AUTOSAR XML (schema 4-0-3)
package /CFLR_Code_pkg/CFLR_Code_swc
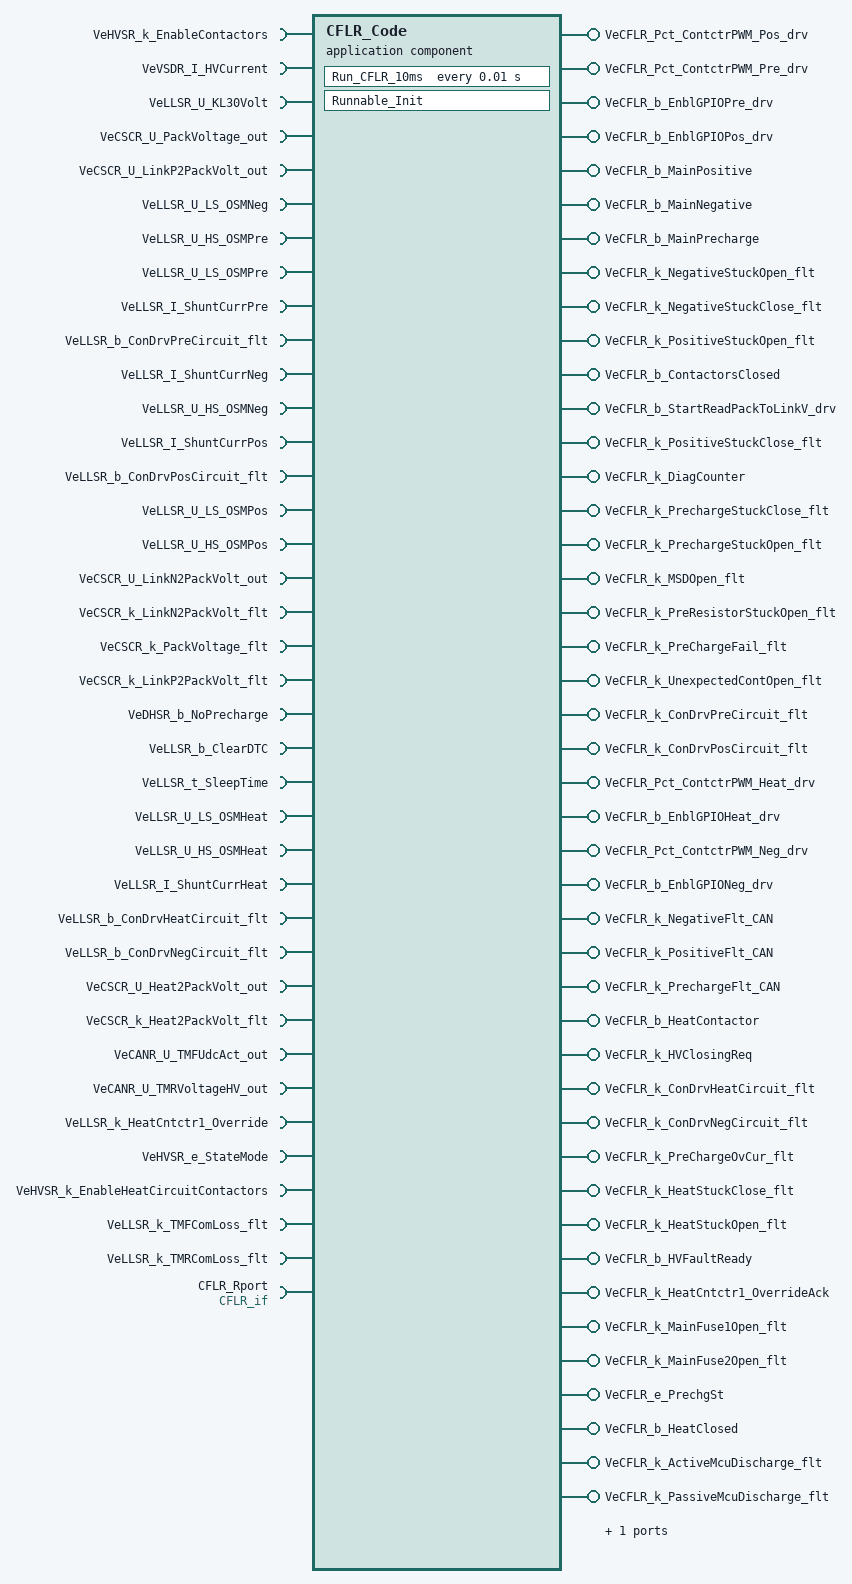
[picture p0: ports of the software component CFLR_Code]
  application sw component type CFLR_Code
    37 x require port:
      VeHVSR_k_EnableContactors: nonqueued-receiver-com-spec{data-element=VeHVSR_k_EnableContactors, init-value=0}, required-interface=VeHVSR_k_EnableContactors
      VeVSDR_I_HVCurrent: nonqueued-receiver-com-spec{data-element=VeVSDR_I_HVCurrent, init-value=0}, required-interface=VeVSDR_I_HVCurrent
      VeLLSR_U_KL30Volt: nonqueued-receiver-com-spec{data-element=VeLLSR_U_KL30Volt, init-value=0}, required-interface=VeLLSR_U_KL30Volt
      VeCSCR_U_PackVoltage_out: nonqueued-receiver-com-spec{data-element=VeCSCR_U_PackVoltage_out, init-value=0}, required-interface=VeCSCR_U_PackVoltage_out
      VeCSCR_U_LinkP2PackVolt_out: nonqueued-receiver-com-spec{data-element=VeCSCR_U_LinkP2PackVolt_out, init-value=0}, required-interface=VeCSCR_U_LinkP2PackVolt_out
      VeLLSR_U_LS_OSMNeg: nonqueued-receiver-com-spec{data-element=VeLLSR_U_LS_OSMNeg, init-value=0}, required-interface=VeLLSR_U_LS_OSMNeg
      VeLLSR_U_HS_OSMPre: nonqueued-receiver-com-spec{data-element=VeLLSR_U_HS_OSMPre, init-value=0}, required-interface=VeLLSR_U_HS_OSMPre
      VeLLSR_U_LS_OSMPre: nonqueued-receiver-com-spec{data-element=VeLLSR_U_LS_OSMPre, init-value=0}, required-interface=VeLLSR_U_LS_OSMPre
      VeLLSR_I_ShuntCurrPre: nonqueued-receiver-com-spec{data-element=VeLLSR_I_ShuntCurrPre, init-value=0}, required-interface=VeLLSR_I_ShuntCurrPre
      VeLLSR_b_ConDrvPreCircuit_flt: nonqueued-receiver-com-spec{data-element=VeLLSR_b_ConDrvPreCircuit_flt, init-value=0}, required-interface=VeLLSR_b_ConDrvPreCircuit_flt
      VeLLSR_I_ShuntCurrNeg: nonqueued-receiver-com-spec{data-element=VeLLSR_I_ShuntCurrNeg, init-value=0}, required-interface=VeLLSR_I_ShuntCurrNeg
      VeLLSR_U_HS_OSMNeg: nonqueued-receiver-com-spec{data-element=VeLLSR_U_HS_OSMNeg, init-value=0}, required-interface=VeLLSR_U_HS_OSMNeg
      VeLLSR_I_ShuntCurrPos: nonqueued-receiver-com-spec{data-element=VeLLSR_I_ShuntCurrPos, init-value=0}, required-interface=VeLLSR_I_ShuntCurrPos
      VeLLSR_b_ConDrvPosCircuit_flt: nonqueued-receiver-com-spec{data-element=VeLLSR_b_ConDrvPosCircuit_flt, init-value=0}, required-interface=VeLLSR_b_ConDrvPosCircuit_flt
      VeLLSR_U_LS_OSMPos: nonqueued-receiver-com-spec{data-element=VeLLSR_U_LS_OSMPos, init-value=0}, required-interface=VeLLSR_U_LS_OSMPos
      VeLLSR_U_HS_OSMPos: nonqueued-receiver-com-spec{data-element=VeLLSR_U_HS_OSMPos, init-value=0}, required-interface=VeLLSR_U_HS_OSMPos
      VeCSCR_U_LinkN2PackVolt_out: nonqueued-receiver-com-spec{data-element=VeCSCR_U_LinkN2PackVolt_out, init-value=0}, required-interface=VeCSCR_U_LinkN2PackVolt_out
      VeCSCR_k_LinkN2PackVolt_flt: nonqueued-receiver-com-spec{data-element=VeCSCR_k_LinkN2PackVolt_flt, init-value=0}, required-interface=VeCSCR_k_LinkN2PackVolt_flt
      VeCSCR_k_PackVoltage_flt: nonqueued-receiver-com-spec{data-element=VeCSCR_k_PackVoltage_flt, init-value=0}, required-interface=VeCSCR_k_PackVoltage_flt
      VeCSCR_k_LinkP2PackVolt_flt: nonqueued-receiver-com-spec{data-element=VeCSCR_k_LinkP2PackVolt_flt, init-value=0}, required-interface=VeCSCR_k_LinkP2PackVolt_flt
      VeDHSR_b_NoPrecharge: nonqueued-receiver-com-spec{data-element=VeDHSR_b_NoPrecharge, init-value=0}, required-interface=VeDHSR_b_NoPrecharge
      VeLLSR_b_ClearDTC: nonqueued-receiver-com-spec{data-element=VeLLSR_b_ClearDTC, init-value=0}, required-interface=VeLLSR_b_ClearDTC
      VeLLSR_t_SleepTime: nonqueued-receiver-com-spec{data-element=VeLLSR_t_SleepTime, init-value=0}, required-interface=VeLLSR_t_SleepTime
      VeLLSR_U_LS_OSMHeat: nonqueued-receiver-com-spec{data-element=VeLLSR_U_LS_OSMHeat, init-value=0}, required-interface=VeLLSR_U_LS_OSMHeat
      VeLLSR_U_HS_OSMHeat: nonqueued-receiver-com-spec{data-element=VeLLSR_U_HS_OSMHeat, init-value=0}, required-interface=VeLLSR_U_HS_OSMHeat
      VeLLSR_I_ShuntCurrHeat: nonqueued-receiver-com-spec{data-element=VeLLSR_I_ShuntCurrHeat, init-value=0}, required-interface=VeLLSR_I_ShuntCurrHeat
      VeLLSR_b_ConDrvHeatCircuit_flt: nonqueued-receiver-com-spec{data-element=VeLLSR_b_ConDrvHeatCircuit_flt, init-value=0}, required-interface=VeLLSR_b_ConDrvHeatCircuit_flt
      VeLLSR_b_ConDrvNegCircuit_flt: nonqueued-receiver-com-spec{data-element=VeLLSR_b_ConDrvNegCircuit_flt, init-value=0}, required-interface=VeLLSR_b_ConDrvNegCircuit_flt
      VeCSCR_U_Heat2PackVolt_out: nonqueued-receiver-com-spec{data-element=VeCSCR_U_Heat2PackVolt_out, init-value=0}, required-interface=VeCSCR_U_Heat2PackVolt_out
      VeCSCR_k_Heat2PackVolt_flt: nonqueued-receiver-com-spec{data-element=VeCSCR_k_Heat2PackVolt_flt, init-value=0}, required-interface=VeCSCR_k_Heat2PackVolt_flt
      VeCANR_U_TMFUdcAct_out: nonqueued-receiver-com-spec{data-element=VeCANR_U_TMFUdcAct_out, init-value=0}, required-interface=VeCANR_U_TMFUdcAct_out
      VeCANR_U_TMRVoltageHV_out: nonqueued-receiver-com-spec{data-element=VeCANR_U_TMRVoltageHV_out, init-value=0}, required-interface=VeCANR_U_TMRVoltageHV_out
      VeLLSR_k_HeatCntctr1_Override: nonqueued-receiver-com-spec{data-element=VeLLSR_k_HeatCntctr1_Override, init-value=0}, required-interface=VeLLSR_k_HeatCntctr1_Override
      VeHVSR_e_StateMode: nonqueued-receiver-com-spec{data-element=VeHVSR_e_StateMode, init-value=CeHVSR_e_StateModeReserved}, required-interface=VeHVSR_e_StateMode
      VeHVSR_k_EnableHeatCircuitContactors: nonqueued-receiver-com-spec{data-element=VeHVSR_k_EnableHeatCircuitContactors, init-value=0}, required-interface=VeHVSR_k_EnableHeatCircuitContactors
      VeLLSR_k_TMFComLoss_flt: nonqueued-receiver-com-spec{data-element=VeLLSR_k_TMFComLoss_flt, init-value=0}, required-interface=VeLLSR_k_TMFComLoss_flt
      VeLLSR_k_TMRComLoss_flt: nonqueued-receiver-com-spec{data-element=VeLLSR_k_TMRComLoss_flt, init-value=0}, required-interface=VeLLSR_k_TMRComLoss_flt
    45 x provide port:
      VeCFLR_Pct_ContctrPWM_Pos_drv: nonqueued-sender-com-spec{data-element=VeCFLR_Pct_ContctrPWM_Pos_drv, init-value=0}, provided-interface=VeCFLR_Pct_ContctrPWM_Pos_drv
      VeCFLR_Pct_ContctrPWM_Pre_drv: nonqueued-sender-com-spec{data-element=VeCFLR_Pct_ContctrPWM_Pre_drv, init-value=0}, provided-interface=VeCFLR_Pct_ContctrPWM_Pre_drv
      VeCFLR_b_EnblGPIOPre_drv: nonqueued-sender-com-spec{data-element=VeCFLR_b_EnblGPIOPre_drv, init-value=0}, provided-interface=VeCFLR_b_EnblGPIOPre_drv
      VeCFLR_b_EnblGPIOPos_drv: nonqueued-sender-com-spec{data-element=VeCFLR_b_EnblGPIOPos_drv, init-value=0}, provided-interface=VeCFLR_b_EnblGPIOPos_drv
      VeCFLR_b_MainPositive: nonqueued-sender-com-spec{data-element=VeCFLR_b_MainPositive, init-value=0}, provided-interface=VeCFLR_b_MainPositive
      VeCFLR_b_MainNegative: nonqueued-sender-com-spec{data-element=VeCFLR_b_MainNegative, init-value=0}, provided-interface=VeCFLR_b_MainNegative
      VeCFLR_b_MainPrecharge: nonqueued-sender-com-spec{data-element=VeCFLR_b_MainPrecharge, init-value=0}, provided-interface=VeCFLR_b_MainPrecharge
      VeCFLR_k_NegativeStuckOpen_flt: nonqueued-sender-com-spec{data-element=VeCFLR_k_NegativeStuckOpen_flt, init-value=0}, provided-interface=VeCFLR_k_NegativeStuckOpen_flt
      VeCFLR_k_NegativeStuckClose_flt: nonqueued-sender-com-spec{data-element=VeCFLR_k_NegativeStuckClose_flt, init-value=0}, provided-interface=VeCFLR_k_NegativeStuckClose_flt
      VeCFLR_k_PositiveStuckOpen_flt: nonqueued-sender-com-spec{data-element=VeCFLR_k_PositiveStuckOpen_flt, init-value=0}, provided-interface=VeCFLR_k_PositiveStuckOpen_flt
      VeCFLR_b_ContactorsClosed: nonqueued-sender-com-spec{data-element=VeCFLR_b_ContactorsClosed, init-value=0}, provided-interface=VeCFLR_b_ContactorsClosed
      VeCFLR_b_StartReadPackToLinkV_drv: nonqueued-sender-com-spec{data-element=VeCFLR_b_StartReadPackToLinkV_drv, init-value=0}, provided-interface=VeCFLR_b_StartReadPackToLinkV_drv
      VeCFLR_k_PositiveStuckClose_flt: nonqueued-sender-com-spec{data-element=VeCFLR_k_PositiveStuckClose_flt, init-value=0}, provided-interface=VeCFLR_k_PositiveStuckClose_flt
      VeCFLR_k_DiagCounter: nonqueued-sender-com-spec{data-element=VeCFLR_k_DiagCounter, init-value=0}, provided-interface=VeCFLR_k_DiagCounter
      VeCFLR_k_PrechargeStuckClose_flt: nonqueued-sender-com-spec{data-element=VeCFLR_k_PrechargeStuckClose_flt, init-value=0}, provided-interface=VeCFLR_k_PrechargeStuckClose_flt
      VeCFLR_k_PrechargeStuckOpen_flt: nonqueued-sender-com-spec{data-element=VeCFLR_k_PrechargeStuckOpen_flt, init-value=0}, provided-interface=VeCFLR_k_PrechargeStuckOpen_flt
      VeCFLR_k_MSDOpen_flt: nonqueued-sender-com-spec{data-element=VeCFLR_k_MSDOpen_flt, init-value=0}, provided-interface=VeCFLR_k_MSDOpen_flt
      VeCFLR_k_PreResistorStuckOpen_flt: nonqueued-sender-com-spec{data-element=VeCFLR_k_PreResistorStuckOpen_flt, init-value=0}, provided-interface=VeCFLR_k_PreResistorStuckOpen_flt
      VeCFLR_k_PreChargeFail_flt: nonqueued-sender-com-spec{data-element=VeCFLR_k_PreChargeFail_flt, init-value=0}, provided-interface=VeCFLR_k_PreChargeFail_flt
      VeCFLR_k_UnexpectedContOpen_flt: nonqueued-sender-com-spec{data-element=VeCFLR_k_UnexpectedContOpen_flt, init-value=0}, provided-interface=VeCFLR_k_UnexpectedContOpen_flt
      VeCFLR_k_ConDrvPreCircuit_flt: nonqueued-sender-com-spec{data-element=VeCFLR_k_ConDrvPreCircuit_flt, init-value=0}, provided-interface=VeCFLR_k_ConDrvPreCircuit_flt
      VeCFLR_k_ConDrvPosCircuit_flt: nonqueued-sender-com-spec{data-element=VeCFLR_k_ConDrvPosCircuit_flt, init-value=0}, provided-interface=VeCFLR_k_ConDrvPosCircuit_flt
      VeCFLR_Pct_ContctrPWM_Heat_drv: nonqueued-sender-com-spec{data-element=VeCFLR_Pct_ContctrPWM_Heat_drv, init-value=0}, provided-interface=VeCFLR_Pct_ContctrPWM_Heat_drv
      VeCFLR_b_EnblGPIOHeat_drv: nonqueued-sender-com-spec{data-element=VeCFLR_b_EnblGPIOHeat_drv, init-value=0}, provided-interface=VeCFLR_b_EnblGPIOHeat_drv
      VeCFLR_Pct_ContctrPWM_Neg_drv: nonqueued-sender-com-spec{data-element=VeCFLR_Pct_ContctrPWM_Neg_drv, init-value=0}, provided-interface=VeCFLR_Pct_ContctrPWM_Neg_drv
      VeCFLR_b_EnblGPIONeg_drv: nonqueued-sender-com-spec{data-element=VeCFLR_b_EnblGPIONeg_drv, init-value=0}, provided-interface=VeCFLR_b_EnblGPIONeg_drv
      VeCFLR_k_NegativeFlt_CAN: nonqueued-sender-com-spec{data-element=VeCFLR_k_NegativeFlt_CAN, init-value=0}, provided-interface=VeCFLR_k_NegativeFlt_CAN
      VeCFLR_k_PositiveFlt_CAN: nonqueued-sender-com-spec{data-element=VeCFLR_k_PositiveFlt_CAN, init-value=0}, provided-interface=VeCFLR_k_PositiveFlt_CAN
      VeCFLR_k_PrechargeFlt_CAN: nonqueued-sender-com-spec{data-element=VeCFLR_k_PrechargeFlt_CAN, init-value=0}, provided-interface=VeCFLR_k_PrechargeFlt_CAN
      VeCFLR_b_HeatContactor: nonqueued-sender-com-spec{data-element=VeCFLR_b_HeatContactor, init-value=0}, provided-interface=VeCFLR_b_HeatContactor
      VeCFLR_k_HVClosingReq: nonqueued-sender-com-spec{data-element=VeCFLR_k_HVClosingReq, init-value=0}, provided-interface=VeCFLR_k_HVClosingReq
      VeCFLR_k_ConDrvHeatCircuit_flt: nonqueued-sender-com-spec{data-element=VeCFLR_k_ConDrvHeatCircuit_flt, init-value=0}, provided-interface=VeCFLR_k_ConDrvHeatCircuit_flt
      VeCFLR_k_ConDrvNegCircuit_flt: nonqueued-sender-com-spec{data-element=VeCFLR_k_ConDrvNegCircuit_flt, init-value=0}, provided-interface=VeCFLR_k_ConDrvNegCircuit_flt
      VeCFLR_k_PreChargeOvCur_flt: nonqueued-sender-com-spec{data-element=VeCFLR_k_PreChargeOvCur_flt, init-value=0}, provided-interface=VeCFLR_k_PreChargeOvCur_flt
      VeCFLR_k_HeatStuckClose_flt: nonqueued-sender-com-spec{data-element=VeCFLR_k_HeatStuckClose_flt, init-value=0}, provided-interface=VeCFLR_k_HeatStuckClose_flt
      VeCFLR_k_HeatStuckOpen_flt: nonqueued-sender-com-spec{data-element=VeCFLR_k_HeatStuckOpen_flt, init-value=0}, provided-interface=VeCFLR_k_HeatStuckOpen_flt
      VeCFLR_b_HVFaultReady: nonqueued-sender-com-spec{data-element=VeCFLR_b_HVFaultReady, init-value=0}, provided-interface=VeCFLR_b_HVFaultReady
      VeCFLR_k_HeatCntctr1_OverrideAck: nonqueued-sender-com-spec{data-element=VeCFLR_k_HeatCntctr1_OverrideAck, init-value=0}, provided-interface=VeCFLR_k_HeatCntctr1_OverrideAck
      VeCFLR_k_MainFuse1Open_flt: nonqueued-sender-com-spec{data-element=VeCFLR_k_MainFuse1Open_flt, init-value=0}, provided-interface=VeCFLR_k_MainFuse1Open_flt
      VeCFLR_k_MainFuse2Open_flt: nonqueued-sender-com-spec{data-element=VeCFLR_k_MainFuse2Open_flt, init-value=0}, provided-interface=VeCFLR_k_MainFuse2Open_flt
      VeCFLR_e_PrechgSt: nonqueued-sender-com-spec{data-element=VeCFLR_e_PrechgSt, init-value=CeCFLR_e_PrechgDefault}, provided-interface=VeCFLR_e_PrechgSt
      VeCFLR_b_HeatClosed: nonqueued-sender-com-spec{data-element=VeCFLR_b_HeatClosed, init-value=0}, provided-interface=VeCFLR_b_HeatClosed
      VeCFLR_k_ActiveMcuDischarge_flt: nonqueued-sender-com-spec{data-element=VeCFLR_k_ActiveMcuDischarge_flt, init-value=0}, provided-interface=VeCFLR_k_ActiveMcuDischarge_flt
      VeCFLR_k_PassiveMcuDischarge_flt: nonqueued-sender-com-spec{data-element=VeCFLR_k_PassiveMcuDischarge_flt, init-value=0}, provided-interface=VeCFLR_k_PassiveMcuDischarge_flt
      VeCFLR_k_RelayOverLoad_flt: nonqueued-sender-com-spec{data-element=VeCFLR_k_RelayOverLoad_flt, init-value=0}, provided-interface=VeCFLR_k_RelayOverLoad_flt
    require port CFLR_Rport: required-interface=CFLR_if
    behavior CFLR_Code: data-type-mapping=CFLR_CodeDataTypeMappingsSet, handle-termination-and-restart=NO-SUPPORT
      7 x exclusive area:
        EA_NeCFLR_t_InitW8Time
        EA_NaCFLR_t_PreChTimer
        EA_NeCFLR_t_LifeTime
        EA_NeCFLR_Cnt_FaultCounter
        EA_NeCFLR_k_PreStart
        EA_NeCFLR_k_PreEnd
        EA_NeCFLR_b_PreChProtect
      static-memorys:
        8 x data, all with sw-calibration-access=READ-ONLY:
          VeCFLR_k_CommandState: category=VALUE, type=UInt8
          VeCFLR_k_InternalState: category=VALUE, type=UInt8
          VeCFLR_k_DiagCounterCmd: category=VALUE, type=UInt8
          VeCFLR_b_EnableContactorsDiag: category=BOOLEAN, type=Boolean
          VeCFLR_k_PreContactorState: category=VALUE, type=TeCFLR_e_Contactor_SystemSts
          VeCFLR_k_PosContactorState: category=VALUE, type=TeCFLR_e_Contactor_SystemSts
          VeCFLR_k_NegContactorState: category=VALUE, type=TeCFLR_e_Contactor_SystemSts
          VeCFLR_k_HeatContactorState: category=VALUE, type=TeCFLR_e_Contactor_SystemSts
      timing event Event_Run_CFLR_10ms: start-on-event=Run_CFLR_10ms, period=0.01
      7 x per instance memory:
        NeCFLR_t_InitW8Time: implementation-data-type=Float, type=NeCFLR_t_InitW8Time_Float, type-definition=Float
        NaCFLR_t_PreChTimer: implementation-data-type=rt_Array_Float_5, type=NaCFLR_t_PreChTimer_rt_Array_Float_5, type-definition=rt_Array_Float_5
        NeCFLR_t_LifeTime: implementation-data-type=Float, type=NeCFLR_t_LifeTime_Float, type-definition=Float
        NeCFLR_Cnt_FaultCounter: implementation-data-type=UInt8, type=NeCFLR_Cnt_FaultCounter_UInt8, type-definition=UInt8
        NeCFLR_k_PreStart: implementation-data-type=UInt8, type=NeCFLR_k_PreStart_UInt8, type-definition=UInt8
        NeCFLR_k_PreEnd: implementation-data-type=UInt8, type=NeCFLR_k_PreEnd_UInt8, type-definition=UInt8
        NeCFLR_b_PreChProtect: implementation-data-type=Boolean, type=NeCFLR_b_PreChProtect_Boolean, type-definition=Boolean
      runnable Runnable_Init: symbol=CFLR_Code_Init
      runnable Run_CFLR_10ms: runs-inside-exclusive-area=[EA_NaCFLR_t_PreChTimer, EA_NeCFLR_b_PreChProtect, EA_NeCFLR_k_PreEnd, EA_NeCFLR_k_PreStart, EA_NeCFLR_t_InitW8Time, EA_NeCFLR_t_LifeTime]
        data-read-access:
          37 x access:
            IN_VeCANR_U_TMFUdcAct_out_VeCANR_U_TMFUdcAct_out: accessed-variable=VeCANR_U_TMFUdcAct_out.VeCANR_U_TMFUdcAct_out
            IN_VeCANR_U_TMRVoltageHV_out_VeCANR_U_TMRVoltageHV_out: accessed-variable=VeCANR_U_TMRVoltageHV_out.VeCANR_U_TMRVoltageHV_out
            IN_VeCSCR_U_Heat2PackVolt_out_VeCSCR_U_Heat2PackVolt_out: accessed-variable=VeCSCR_U_Heat2PackVolt_out.VeCSCR_U_Heat2PackVolt_out
            IN_VeCSCR_U_LinkN2PackVolt_out_VeCSCR_U_LinkN2PackVolt_out: accessed-variable=VeCSCR_U_LinkN2PackVolt_out.VeCSCR_U_LinkN2PackVolt_out
            IN_VeCSCR_U_LinkP2PackVolt_out_VeCSCR_U_LinkP2PackVolt_out: accessed-variable=VeCSCR_U_LinkP2PackVolt_out.VeCSCR_U_LinkP2PackVolt_out
            IN_VeCSCR_U_PackVoltage_out_VeCSCR_U_PackVoltage_out: accessed-variable=VeCSCR_U_PackVoltage_out.VeCSCR_U_PackVoltage_out
            IN_VeCSCR_k_Heat2PackVolt_flt_VeCSCR_k_Heat2PackVolt_flt: accessed-variable=VeCSCR_k_Heat2PackVolt_flt.VeCSCR_k_Heat2PackVolt_flt
            IN_VeCSCR_k_LinkN2PackVolt_flt_VeCSCR_k_LinkN2PackVolt_flt: accessed-variable=VeCSCR_k_LinkN2PackVolt_flt.VeCSCR_k_LinkN2PackVolt_flt
            IN_VeCSCR_k_LinkP2PackVolt_flt_VeCSCR_k_LinkP2PackVolt_flt: accessed-variable=VeCSCR_k_LinkP2PackVolt_flt.VeCSCR_k_LinkP2PackVolt_flt
            IN_VeCSCR_k_PackVoltage_flt_VeCSCR_k_PackVoltage_flt: accessed-variable=VeCSCR_k_PackVoltage_flt.VeCSCR_k_PackVoltage_flt
            IN_VeDHSR_b_NoPrecharge_VeDHSR_b_NoPrecharge: accessed-variable=VeDHSR_b_NoPrecharge.VeDHSR_b_NoPrecharge
            IN_VeHVSR_e_StateMode_VeHVSR_e_StateMode: accessed-variable=VeHVSR_e_StateMode.VeHVSR_e_StateMode
            IN_VeHVSR_k_EnableContactors_VeHVSR_k_EnableContactors: accessed-variable=VeHVSR_k_EnableContactors.VeHVSR_k_EnableContactors
            IN_VeHVSR_k_EnableHeatCircuitContactors_VeHVS_4d715a757cc8564f: accessed-variable=VeHVSR_k_EnableHeatCircuitContactors.VeHVSR_k_EnableHeatCircuitContactors
            IN_VeLLSR_I_ShuntCurrHeat_VeLLSR_I_ShuntCurrHeat: accessed-variable=VeLLSR_I_ShuntCurrHeat.VeLLSR_I_ShuntCurrHeat
            IN_VeLLSR_I_ShuntCurrNeg_VeLLSR_I_ShuntCurrNeg: accessed-variable=VeLLSR_I_ShuntCurrNeg.VeLLSR_I_ShuntCurrNeg
            IN_VeLLSR_I_ShuntCurrPos_VeLLSR_I_ShuntCurrPos: accessed-variable=VeLLSR_I_ShuntCurrPos.VeLLSR_I_ShuntCurrPos
            IN_VeLLSR_I_ShuntCurrPre_VeLLSR_I_ShuntCurrPre: accessed-variable=VeLLSR_I_ShuntCurrPre.VeLLSR_I_ShuntCurrPre
            IN_VeLLSR_U_HS_OSMHeat_VeLLSR_U_HS_OSMHeat: accessed-variable=VeLLSR_U_HS_OSMHeat.VeLLSR_U_HS_OSMHeat
            IN_VeLLSR_U_HS_OSMNeg_VeLLSR_U_HS_OSMNeg: accessed-variable=VeLLSR_U_HS_OSMNeg.VeLLSR_U_HS_OSMNeg
            IN_VeLLSR_U_HS_OSMPos_VeLLSR_U_HS_OSMPos: accessed-variable=VeLLSR_U_HS_OSMPos.VeLLSR_U_HS_OSMPos
            IN_VeLLSR_U_HS_OSMPre_VeLLSR_U_HS_OSMPre: accessed-variable=VeLLSR_U_HS_OSMPre.VeLLSR_U_HS_OSMPre
            IN_VeLLSR_U_KL30Volt_VeLLSR_U_KL30Volt: accessed-variable=VeLLSR_U_KL30Volt.VeLLSR_U_KL30Volt
            IN_VeLLSR_U_LS_OSMHeat_VeLLSR_U_LS_OSMHeat: accessed-variable=VeLLSR_U_LS_OSMHeat.VeLLSR_U_LS_OSMHeat
            IN_VeLLSR_U_LS_OSMNeg_VeLLSR_U_LS_OSMNeg: accessed-variable=VeLLSR_U_LS_OSMNeg.VeLLSR_U_LS_OSMNeg
            IN_VeLLSR_U_LS_OSMPos_VeLLSR_U_LS_OSMPos: accessed-variable=VeLLSR_U_LS_OSMPos.VeLLSR_U_LS_OSMPos
            IN_VeLLSR_U_LS_OSMPre_VeLLSR_U_LS_OSMPre: accessed-variable=VeLLSR_U_LS_OSMPre.VeLLSR_U_LS_OSMPre
            IN_VeLLSR_b_ClearDTC_VeLLSR_b_ClearDTC: accessed-variable=VeLLSR_b_ClearDTC.VeLLSR_b_ClearDTC
            IN_VeLLSR_b_ConDrvHeatCircuit_flt_VeLLSR_b_Co_ee309d020680cb44: accessed-variable=VeLLSR_b_ConDrvHeatCircuit_flt.VeLLSR_b_ConDrvHeatCircuit_flt
            IN_VeLLSR_b_ConDrvNegCircuit_flt_VeLLSR_b_ConDrvNegCircuit_flt: accessed-variable=VeLLSR_b_ConDrvNegCircuit_flt.VeLLSR_b_ConDrvNegCircuit_flt
            IN_VeLLSR_b_ConDrvPosCircuit_flt_VeLLSR_b_ConDrvPosCircuit_flt: accessed-variable=VeLLSR_b_ConDrvPosCircuit_flt.VeLLSR_b_ConDrvPosCircuit_flt
            IN_VeLLSR_b_ConDrvPreCircuit_flt_VeLLSR_b_ConDrvPreCircuit_flt: accessed-variable=VeLLSR_b_ConDrvPreCircuit_flt.VeLLSR_b_ConDrvPreCircuit_flt
            IN_VeLLSR_k_HeatCntctr1_Override_VeLLSR_k_HeatCntctr1_Override: accessed-variable=VeLLSR_k_HeatCntctr1_Override.VeLLSR_k_HeatCntctr1_Override
            IN_VeLLSR_k_TMFComLoss_flt_VeLLSR_k_TMFComLoss_flt: accessed-variable=VeLLSR_k_TMFComLoss_flt.VeLLSR_k_TMFComLoss_flt
            IN_VeLLSR_k_TMRComLoss_flt_VeLLSR_k_TMRComLoss_flt: accessed-variable=VeLLSR_k_TMRComLoss_flt.VeLLSR_k_TMRComLoss_flt
            IN_VeLLSR_t_SleepTime_VeLLSR_t_SleepTime: accessed-variable=VeLLSR_t_SleepTime.VeLLSR_t_SleepTime
            IN_VeVSDR_I_HVCurrent_VeVSDR_I_HVCurrent: accessed-variable=VeVSDR_I_HVCurrent.VeVSDR_I_HVCurrent
        data-send-points:
          45 x access:
            OUT_VeCFLR_Pct_ContctrPWM_Pos_drv_VeCFLR_Pct_cdf9f7f545af5c7b: accessed-variable=VeCFLR_Pct_ContctrPWM_Pos_drv.VeCFLR_Pct_ContctrPWM_Pos_drv
            OUT_VeCFLR_Pct_ContctrPWM_Pre_drv_VeCFLR_Pct_e76e52cbd7820085: accessed-variable=VeCFLR_Pct_ContctrPWM_Pre_drv.VeCFLR_Pct_ContctrPWM_Pre_drv
            OUT_VeCFLR_b_EnblGPIOPre_drv_VeCFLR_b_EnblGPIOPre_drv: accessed-variable=VeCFLR_b_EnblGPIOPre_drv.VeCFLR_b_EnblGPIOPre_drv
            OUT_VeCFLR_b_EnblGPIOPos_drv_VeCFLR_b_EnblGPIOPos_drv: accessed-variable=VeCFLR_b_EnblGPIOPos_drv.VeCFLR_b_EnblGPIOPos_drv
            OUT_VeCFLR_b_MainPositive_VeCFLR_b_MainPositive: accessed-variable=VeCFLR_b_MainPositive.VeCFLR_b_MainPositive
            OUT_VeCFLR_b_MainNegative_VeCFLR_b_MainNegative: accessed-variable=VeCFLR_b_MainNegative.VeCFLR_b_MainNegative
            OUT_VeCFLR_b_MainPrecharge_VeCFLR_b_MainPrecharge: accessed-variable=VeCFLR_b_MainPrecharge.VeCFLR_b_MainPrecharge
            OUT_VeCFLR_k_NegativeStuckOpen_flt_VeCFLR_k_N_0a2b52ea423b9133: accessed-variable=VeCFLR_k_NegativeStuckOpen_flt.VeCFLR_k_NegativeStuckOpen_flt
            OUT_VeCFLR_k_NegativeStuckClose_flt_VeCFLR_k_ccaba6835c2399ea: accessed-variable=VeCFLR_k_NegativeStuckClose_flt.VeCFLR_k_NegativeStuckClose_flt
            OUT_VeCFLR_k_PositiveStuckOpen_flt_VeCFLR_k_P_c7986300e0c97148: accessed-variable=VeCFLR_k_PositiveStuckOpen_flt.VeCFLR_k_PositiveStuckOpen_flt
            OUT_VeCFLR_b_ContactorsClosed_VeCFLR_b_ContactorsClosed: accessed-variable=VeCFLR_b_ContactorsClosed.VeCFLR_b_ContactorsClosed
            OUT_VeCFLR_b_StartReadPackToLinkV_drv_VeCFLR_8c475b8ec366ac06: accessed-variable=VeCFLR_b_StartReadPackToLinkV_drv.VeCFLR_b_StartReadPackToLinkV_drv
            OUT_VeCFLR_k_PositiveStuckClose_flt_VeCFLR_k_b2bb26b23e3c8721: accessed-variable=VeCFLR_k_PositiveStuckClose_flt.VeCFLR_k_PositiveStuckClose_flt
            OUT_VeCFLR_k_DiagCounter_VeCFLR_k_DiagCounter: accessed-variable=VeCFLR_k_DiagCounter.VeCFLR_k_DiagCounter
            OUT_VeCFLR_k_PrechargeStuckClose_flt_VeCFLR_k_5bda8ec5f46ceddd: accessed-variable=VeCFLR_k_PrechargeStuckClose_flt.VeCFLR_k_PrechargeStuckClose_flt
            OUT_VeCFLR_k_PrechargeStuckOpen_flt_VeCFLR_k_d0397e6dac1956c1: accessed-variable=VeCFLR_k_PrechargeStuckOpen_flt.VeCFLR_k_PrechargeStuckOpen_flt
            OUT_VeCFLR_k_MSDOpen_flt_VeCFLR_k_MSDOpen_flt: accessed-variable=VeCFLR_k_MSDOpen_flt.VeCFLR_k_MSDOpen_flt
            OUT_VeCFLR_k_PreResistorStuckOpen_flt_VeCFLR_4ac7688cf178b440: accessed-variable=VeCFLR_k_PreResistorStuckOpen_flt.VeCFLR_k_PreResistorStuckOpen_flt
            OUT_VeCFLR_k_PreChargeFail_flt_VeCFLR_k_PreChargeFail_flt: accessed-variable=VeCFLR_k_PreChargeFail_flt.VeCFLR_k_PreChargeFail_flt
            OUT_VeCFLR_k_UnexpectedContOpen_flt_VeCFLR_k_66830968cb4800d5: accessed-variable=VeCFLR_k_UnexpectedContOpen_flt.VeCFLR_k_UnexpectedContOpen_flt
            OUT_VeCFLR_k_ConDrvPreCircuit_flt_VeCFLR_k_Co_f28f50d6f999a07a: accessed-variable=VeCFLR_k_ConDrvPreCircuit_flt.VeCFLR_k_ConDrvPreCircuit_flt
            OUT_VeCFLR_k_ConDrvPosCircuit_flt_VeCFLR_k_Co_1e5617fde0bd58e1: accessed-variable=VeCFLR_k_ConDrvPosCircuit_flt.VeCFLR_k_ConDrvPosCircuit_flt
            OUT_VeCFLR_Pct_ContctrPWM_Heat_drv_VeCFLR_Pct_69b109d3a80e4ff4: accessed-variable=VeCFLR_Pct_ContctrPWM_Heat_drv.VeCFLR_Pct_ContctrPWM_Heat_drv
            OUT_VeCFLR_b_EnblGPIOHeat_drv_VeCFLR_b_EnblGPIOHeat_drv: accessed-variable=VeCFLR_b_EnblGPIOHeat_drv.VeCFLR_b_EnblGPIOHeat_drv
            OUT_VeCFLR_Pct_ContctrPWM_Neg_drv_VeCFLR_Pct_137dd9156de13d12: accessed-variable=VeCFLR_Pct_ContctrPWM_Neg_drv.VeCFLR_Pct_ContctrPWM_Neg_drv
            OUT_VeCFLR_b_EnblGPIONeg_drv_VeCFLR_b_EnblGPIONeg_drv: accessed-variable=VeCFLR_b_EnblGPIONeg_drv.VeCFLR_b_EnblGPIONeg_drv
            OUT_VeCFLR_k_NegativeFlt_CAN_VeCFLR_k_NegativeFlt_CAN: accessed-variable=VeCFLR_k_NegativeFlt_CAN.VeCFLR_k_NegativeFlt_CAN
            OUT_VeCFLR_k_PositiveFlt_CAN_VeCFLR_k_PositiveFlt_CAN: accessed-variable=VeCFLR_k_PositiveFlt_CAN.VeCFLR_k_PositiveFlt_CAN
            OUT_VeCFLR_k_PrechargeFlt_CAN_VeCFLR_k_PrechargeFlt_CAN: accessed-variable=VeCFLR_k_PrechargeFlt_CAN.VeCFLR_k_PrechargeFlt_CAN
            OUT_VeCFLR_b_HeatContactor_VeCFLR_b_HeatContactor: accessed-variable=VeCFLR_b_HeatContactor.VeCFLR_b_HeatContactor
            OUT_VeCFLR_k_HVClosingReq_VeCFLR_k_HVClosingReq: accessed-variable=VeCFLR_k_HVClosingReq.VeCFLR_k_HVClosingReq
            OUT_VeCFLR_k_ConDrvHeatCircuit_flt_VeCFLR_k_C_4d8ba6c9d633f948: accessed-variable=VeCFLR_k_ConDrvHeatCircuit_flt.VeCFLR_k_ConDrvHeatCircuit_flt
            OUT_VeCFLR_k_ConDrvNegCircuit_flt_VeCFLR_k_Co_466cd38cca19ff2c: accessed-variable=VeCFLR_k_ConDrvNegCircuit_flt.VeCFLR_k_ConDrvNegCircuit_flt
            OUT_VeCFLR_k_PreChargeOvCur_flt_VeCFLR_k_PreChargeOvCur_flt: accessed-variable=VeCFLR_k_PreChargeOvCur_flt.VeCFLR_k_PreChargeOvCur_flt
            OUT_VeCFLR_k_HeatStuckClose_flt_VeCFLR_k_HeatStuckClose_flt: accessed-variable=VeCFLR_k_HeatStuckClose_flt.VeCFLR_k_HeatStuckClose_flt
            OUT_VeCFLR_k_HeatStuckOpen_flt_VeCFLR_k_HeatStuckOpen_flt: accessed-variable=VeCFLR_k_HeatStuckOpen_flt.VeCFLR_k_HeatStuckOpen_flt
            OUT_VeCFLR_b_HVFaultReady_VeCFLR_b_HVFaultReady: accessed-variable=VeCFLR_b_HVFaultReady.VeCFLR_b_HVFaultReady
            OUT_VeCFLR_k_HeatCntctr1_OverrideAck_VeCFLR_k_ec902e9e13283e03: accessed-variable=VeCFLR_k_HeatCntctr1_OverrideAck.VeCFLR_k_HeatCntctr1_OverrideAck
            OUT_VeCFLR_k_MainFuse1Open_flt_VeCFLR_k_MainFuse1Open_flt: accessed-variable=VeCFLR_k_MainFuse1Open_flt.VeCFLR_k_MainFuse1Open_flt
            OUT_VeCFLR_k_MainFuse2Open_flt_VeCFLR_k_MainFuse2Open_flt: accessed-variable=VeCFLR_k_MainFuse2Open_flt.VeCFLR_k_MainFuse2Open_flt
            OUT_VeCFLR_e_PrechgSt_VeCFLR_e_PrechgSt: accessed-variable=VeCFLR_e_PrechgSt.VeCFLR_e_PrechgSt
            OUT_VeCFLR_b_HeatClosed_VeCFLR_b_HeatClosed: accessed-variable=VeCFLR_b_HeatClosed.VeCFLR_b_HeatClosed
            OUT_VeCFLR_k_ActiveMcuDischarge_flt_VeCFLR_k_0a887831cda3b521: accessed-variable=VeCFLR_k_ActiveMcuDischarge_flt.VeCFLR_k_ActiveMcuDischarge_flt
            OUT_VeCFLR_k_PassiveMcuDischarge_flt_VeCFLR_k_266f203372361099: accessed-variable=VeCFLR_k_PassiveMcuDischarge_flt.VeCFLR_k_PassiveMcuDischarge_flt
            OUT_VeCFLR_k_RelayOverLoad_flt_VeCFLR_k_RelayOverLoad_flt: accessed-variable=VeCFLR_k_RelayOverLoad_flt.VeCFLR_k_RelayOverLoad_flt
        179 x parameter access:
          CALPRM_CFLR_Rport_KeCFLR_Cnt_ClrPrechgProtectTime1: accessed-parameter=CFLR_Rport.KeCFLR_Cnt_ClrPrechgProtectTime1
          CALPRM_CFLR_Rport_KeCFLR_Cnt_ClrPrechgProtectTime2: accessed-parameter=CFLR_Rport.KeCFLR_Cnt_ClrPrechgProtectTime2
          CALPRM_CFLR_Rport_KeCFLR_Cnt_PowDownTimeThresh: accessed-parameter=CFLR_Rport.KeCFLR_Cnt_PowDownTimeThresh
          CALPRM_CFLR_Rport_KeCFLR_Cnt_PreChgProtect: accessed-parameter=CFLR_Rport.KeCFLR_Cnt_PreChgProtect
          CALPRM_CFLR_Rport_KeCFLR_I_CntctrCurrHoldHeat: accessed-parameter=CFLR_Rport.KeCFLR_I_CntctrCurrHoldHeat
          CALPRM_CFLR_Rport_KeCFLR_I_CntctrCurrHoldNeg: accessed-parameter=CFLR_Rport.KeCFLR_I_CntctrCurrHoldNeg
          CALPRM_CFLR_Rport_KeCFLR_I_CntctrCurrHoldPos: accessed-parameter=CFLR_Rport.KeCFLR_I_CntctrCurrHoldPos
          CALPRM_CFLR_Rport_KeCFLR_I_CntctrCurrHoldPre: accessed-parameter=CFLR_Rport.KeCFLR_I_CntctrCurrHoldPre
          CALPRM_CFLR_Rport_KeCFLR_I_MaxCurrOpenCntctr: accessed-parameter=CFLR_Rport.KeCFLR_I_MaxCurrOpenCntctr
          CALPRM_CFLR_Rport_KeCFLR_I_MaxR3Current: accessed-parameter=CFLR_Rport.KeCFLR_I_MaxR3Current
          CALPRM_CFLR_Rport_KeCFLR_I_MinCurrOpenCntctr: accessed-parameter=CFLR_Rport.KeCFLR_I_MinCurrOpenCntctr
          CALPRM_CFLR_Rport_KeCFLR_I_MinR3Current: accessed-parameter=CFLR_Rport.KeCFLR_I_MinR3Current
          CALPRM_CFLR_Rport_KeCFLR_I_OverCurrentThresh: accessed-parameter=CFLR_Rport.KeCFLR_I_OverCurrentThresh
          CALPRM_CFLR_Rport_KeCFLR_I_PowDownCurrentThresh: accessed-parameter=CFLR_Rport.KeCFLR_I_PowDownCurrentThresh
          CALPRM_CFLR_Rport_KeCFLR_I_ZeroCurrentThreshholdLw: accessed-parameter=CFLR_Rport.KeCFLR_I_ZeroCurrentThreshholdLw
          CALPRM_CFLR_Rport_KeCFLR_I_ZeroCurrentThreshholdUp: accessed-parameter=CFLR_Rport.KeCFLR_I_ZeroCurrentThreshholdUp
          CALPRM_CFLR_Rport_KeCFLR_K_KL30VoltageFactorLower: accessed-parameter=CFLR_Rport.KeCFLR_K_KL30VoltageFactorLower
          CALPRM_CFLR_Rport_KeCFLR_K_KL30VoltageFactorUpper: accessed-parameter=CFLR_Rport.KeCFLR_K_KL30VoltageFactorUpper
          CALPRM_CFLR_Rport_KeCFLR_Pct_ContctrPWM_Fsp_drv_Val: accessed-parameter=CFLR_Rport.KeCFLR_Pct_ContctrPWM_Fsp_drv_Val
          CALPRM_CFLR_Rport_KeCFLR_Pct_ContctrPWM_Neg_drv_Val: accessed-parameter=CFLR_Rport.KeCFLR_Pct_ContctrPWM_Neg_drv_Val
          CALPRM_CFLR_Rport_KeCFLR_Pct_ContctrPWM_Pre_drv_En: accessed-parameter=CFLR_Rport.KeCFLR_Pct_ContctrPWM_Pre_drv_En
          CALPRM_CFLR_Rport_KeCFLR_Pct_ContctrPWM_Pre_drv_Val: accessed-parameter=CFLR_Rport.KeCFLR_Pct_ContctrPWM_Pre_drv_Val
          CALPRM_CFLR_Rport_KeCFLR_Pct_SetContctrPWM_PIDPos_En: accessed-parameter=CFLR_Rport.KeCFLR_Pct_SetContctrPWM_PIDPos_En
          CALPRM_CFLR_Rport_KeCFLR_Pct_SetContctrPWM_PIDPos_Val: accessed-parameter=CFLR_Rport.KeCFLR_Pct_SetContctrPWM_PIDPos_Val
          CALPRM_CFLR_Rport_KeCFLR_R_PosResistanceLowLim: accessed-parameter=CFLR_Rport.KeCFLR_R_PosResistanceLowLim
          CALPRM_CFLR_Rport_KeCFLR_R_PosResistanceUpLim: accessed-parameter=CFLR_Rport.KeCFLR_R_PosResistanceUpLim
          CALPRM_CFLR_Rport_KeCFLR_R_PreResistanceLowLim: accessed-parameter=CFLR_Rport.KeCFLR_R_PreResistanceLowLim
          CALPRM_CFLR_Rport_KeCFLR_R_PreResistanceUpLim: accessed-parameter=CFLR_Rport.KeCFLR_R_PreResistanceUpLim
          CALPRM_CFLR_Rport_KeCFLR_U_GroundVoltageHigh: accessed-parameter=CFLR_Rport.KeCFLR_U_GroundVoltageHigh
          CALPRM_CFLR_Rport_KeCFLR_U_GroundVoltageLow: accessed-parameter=CFLR_Rport.KeCFLR_U_GroundVoltageLow
          CALPRM_CFLR_Rport_KeCFLR_U_LinkLessThanPack: accessed-parameter=CFLR_Rport.KeCFLR_U_LinkLessThanPack
          CALPRM_CFLR_Rport_KeCFLR_U_MaxVolt4HS_OSMPos: accessed-parameter=CFLR_Rport.KeCFLR_U_MaxVolt4HS_OSMPos
          CALPRM_CFLR_Rport_KeCFLR_U_MaxVolt4HS_OSMPre: accessed-parameter=CFLR_Rport.KeCFLR_U_MaxVolt4HS_OSMPre
          CALPRM_CFLR_Rport_KeCFLR_U_MaxVolt4LS_OSMPos: accessed-parameter=CFLR_Rport.KeCFLR_U_MaxVolt4LS_OSMPos
          CALPRM_CFLR_Rport_KeCFLR_U_MaxVolt4LS_OSMPre: accessed-parameter=CFLR_Rport.KeCFLR_U_MaxVolt4LS_OSMPre
          CALPRM_CFLR_Rport_KeCFLR_U_McuDischgThreshhold: accessed-parameter=CFLR_Rport.KeCFLR_U_McuDischgThreshhold
          CALPRM_CFLR_Rport_KeCFLR_U_MinVolt4HS_OSMPos: accessed-parameter=CFLR_Rport.KeCFLR_U_MinVolt4HS_OSMPos
          CALPRM_CFLR_Rport_KeCFLR_U_MinVolt4HS_OSMPre: accessed-parameter=CFLR_Rport.KeCFLR_U_MinVolt4HS_OSMPre
          CALPRM_CFLR_Rport_KeCFLR_U_MinVolt4LS_OSMPos: accessed-parameter=CFLR_Rport.KeCFLR_U_MinVolt4LS_OSMPos
          CALPRM_CFLR_Rport_KeCFLR_U_MinVolt4LS_OSMPre: accessed-parameter=CFLR_Rport.KeCFLR_U_MinVolt4LS_OSMPre
          CALPRM_CFLR_Rport_KeCFLR_U_NegConClosedThreshhold: accessed-parameter=CFLR_Rport.KeCFLR_U_NegConClosedThreshhold
          CALPRM_CFLR_Rport_KeCFLR_U_PowerdiffThreshhold: accessed-parameter=CFLR_Rport.KeCFLR_U_PowerdiffThreshhold
          CALPRM_CFLR_Rport_KeCFLR_U_withPowerThreshhold: accessed-parameter=CFLR_Rport.KeCFLR_U_withPowerThreshhold
          CALPRM_CFLR_Rport_KeCFLR_b_ActiveMcuDischarge_En: accessed-parameter=CFLR_Rport.KeCFLR_b_ActiveMcuDischarge_En
          CALPRM_CFLR_Rport_KeCFLR_b_CloseHeat_En: accessed-parameter=CFLR_Rport.KeCFLR_b_CloseHeat_En
          CALPRM_CFLR_Rport_KeCFLR_b_CloseHeat_Val: accessed-parameter=CFLR_Rport.KeCFLR_b_CloseHeat_Val
          CALPRM_CFLR_Rport_KeCFLR_b_CloseNeg_En: accessed-parameter=CFLR_Rport.KeCFLR_b_CloseNeg_En
          CALPRM_CFLR_Rport_KeCFLR_b_CloseNeg_Val: accessed-parameter=CFLR_Rport.KeCFLR_b_CloseNeg_Val
          CALPRM_CFLR_Rport_KeCFLR_b_ClosePos_En: accessed-parameter=CFLR_Rport.KeCFLR_b_ClosePos_En
          CALPRM_CFLR_Rport_KeCFLR_b_ClosePos_Val: accessed-parameter=CFLR_Rport.KeCFLR_b_ClosePos_Val
          CALPRM_CFLR_Rport_KeCFLR_b_ClosePre_En: accessed-parameter=CFLR_Rport.KeCFLR_b_ClosePre_En
          CALPRM_CFLR_Rport_KeCFLR_b_ClosePre_Val: accessed-parameter=CFLR_Rport.KeCFLR_b_ClosePre_Val
          CALPRM_CFLR_Rport_KeCFLR_b_ConDrvHeatCircuit_flt_En: accessed-parameter=CFLR_Rport.KeCFLR_b_ConDrvHeatCircuit_flt_En
          CALPRM_CFLR_Rport_KeCFLR_b_ConDrvNegCircuit_flt_En: accessed-parameter=CFLR_Rport.KeCFLR_b_ConDrvNegCircuit_flt_En
          CALPRM_CFLR_Rport_KeCFLR_b_ConDrvPosCircuit_flt_En: accessed-parameter=CFLR_Rport.KeCFLR_b_ConDrvPosCircuit_flt_En
          CALPRM_CFLR_Rport_KeCFLR_b_ConDrvPreCircuit_flt_En: accessed-parameter=CFLR_Rport.KeCFLR_b_ConDrvPreCircuit_flt_En
          CALPRM_CFLR_Rport_KeCFLR_b_ContactorsClosed_En: accessed-parameter=CFLR_Rport.KeCFLR_b_ContactorsClosed_En
          CALPRM_CFLR_Rport_KeCFLR_b_ContactorsClosed_Val: accessed-parameter=CFLR_Rport.KeCFLR_b_ContactorsClosed_Val
          CALPRM_CFLR_Rport_KeCFLR_b_ContctrPWM_Fsp_drv_En: accessed-parameter=CFLR_Rport.KeCFLR_b_ContctrPWM_Fsp_drv_En
          CALPRM_CFLR_Rport_KeCFLR_b_ContctrPWM_Neg_drv_En: accessed-parameter=CFLR_Rport.KeCFLR_b_ContctrPWM_Neg_drv_En
          CALPRM_CFLR_Rport_KeCFLR_b_EnableContactorsDiag_En: accessed-parameter=CFLR_Rport.KeCFLR_b_EnableContactorsDiag_En
          CALPRM_CFLR_Rport_KeCFLR_b_EnableContactorsDiag_Val: accessed-parameter=CFLR_Rport.KeCFLR_b_EnableContactorsDiag_Val
          CALPRM_CFLR_Rport_KeCFLR_b_EnblGPIOHeat_drv_En: accessed-parameter=CFLR_Rport.KeCFLR_b_EnblGPIOHeat_drv_En
          CALPRM_CFLR_Rport_KeCFLR_b_EnblGPIOHeat_drv_Val: accessed-parameter=CFLR_Rport.KeCFLR_b_EnblGPIOHeat_drv_Val
          CALPRM_CFLR_Rport_KeCFLR_b_EnblGPIONeg_drv_En: accessed-parameter=CFLR_Rport.KeCFLR_b_EnblGPIONeg_drv_En
          CALPRM_CFLR_Rport_KeCFLR_b_EnblGPIONeg_drv_Val: accessed-parameter=CFLR_Rport.KeCFLR_b_EnblGPIONeg_drv_Val
          CALPRM_CFLR_Rport_KeCFLR_b_EnblGPIOPos_drv_En: accessed-parameter=CFLR_Rport.KeCFLR_b_EnblGPIOPos_drv_En
          CALPRM_CFLR_Rport_KeCFLR_b_EnblGPIOPos_drv_Val: accessed-parameter=CFLR_Rport.KeCFLR_b_EnblGPIOPos_drv_Val
          CALPRM_CFLR_Rport_KeCFLR_b_EnblGPIOPre_drv_En: accessed-parameter=CFLR_Rport.KeCFLR_b_EnblGPIOPre_drv_En
          CALPRM_CFLR_Rport_KeCFLR_b_EnblGPIOPre_drv_Val: accessed-parameter=CFLR_Rport.KeCFLR_b_EnblGPIOPre_drv_Val
          CALPRM_CFLR_Rport_KeCFLR_b_ForceOpenContactors: accessed-parameter=CFLR_Rport.KeCFLR_b_ForceOpenContactors
          CALPRM_CFLR_Rport_KeCFLR_b_HVClosingReq_En: accessed-parameter=CFLR_Rport.KeCFLR_b_HVClosingReq_En
          CALPRM_CFLR_Rport_KeCFLR_b_HVFaultReady_En: accessed-parameter=CFLR_Rport.KeCFLR_b_HVFaultReady_En
          CALPRM_CFLR_Rport_KeCFLR_b_HVFaultReady_Val: accessed-parameter=CFLR_Rport.KeCFLR_b_HVFaultReady_Val
          CALPRM_CFLR_Rport_KeCFLR_b_HeatClosed_En: accessed-parameter=CFLR_Rport.KeCFLR_b_HeatClosed_En
          CALPRM_CFLR_Rport_KeCFLR_b_HeatClosed_Val: accessed-parameter=CFLR_Rport.KeCFLR_b_HeatClosed_Val
          CALPRM_CFLR_Rport_KeCFLR_b_HeatCntctr1_OverrideAck_En: accessed-parameter=CFLR_Rport.KeCFLR_b_HeatCntctr1_OverrideAck_En
          CALPRM_CFLR_Rport_KeCFLR_b_HeatConClosed_En: accessed-parameter=CFLR_Rport.KeCFLR_b_HeatConClosed_En
          CALPRM_CFLR_Rport_KeCFLR_b_HeatConClosed_Val: accessed-parameter=CFLR_Rport.KeCFLR_b_HeatConClosed_Val
          CALPRM_CFLR_Rport_KeCFLR_b_HeatStuckClose_flt_En: accessed-parameter=CFLR_Rport.KeCFLR_b_HeatStuckClose_flt_En
          CALPRM_CFLR_Rport_KeCFLR_b_HeatStuckOpen_flt_En: accessed-parameter=CFLR_Rport.KeCFLR_b_HeatStuckOpen_flt_En
          CALPRM_CFLR_Rport_KeCFLR_b_MSDOpenFlt_En: accessed-parameter=CFLR_Rport.KeCFLR_b_MSDOpenFlt_En
          CALPRM_CFLR_Rport_KeCFLR_b_MainFuse1Open_En: accessed-parameter=CFLR_Rport.KeCFLR_b_MainFuse1Open_En
          CALPRM_CFLR_Rport_KeCFLR_b_MainFuse2Open_En: accessed-parameter=CFLR_Rport.KeCFLR_b_MainFuse2Open_En
          CALPRM_CFLR_Rport_KeCFLR_b_MainNegative_En: accessed-parameter=CFLR_Rport.KeCFLR_b_MainNegative_En
          CALPRM_CFLR_Rport_KeCFLR_b_MainNegative_Val: accessed-parameter=CFLR_Rport.KeCFLR_b_MainNegative_Val
          CALPRM_CFLR_Rport_KeCFLR_b_MainPositive_En: accessed-parameter=CFLR_Rport.KeCFLR_b_MainPositive_En
          CALPRM_CFLR_Rport_KeCFLR_b_MainPositive_Val: accessed-parameter=CFLR_Rport.KeCFLR_b_MainPositive_Val
          CALPRM_CFLR_Rport_KeCFLR_b_MainPrecharge_En: accessed-parameter=CFLR_Rport.KeCFLR_b_MainPrecharge_En
          CALPRM_CFLR_Rport_KeCFLR_b_MainPrecharge_Val: accessed-parameter=CFLR_Rport.KeCFLR_b_MainPrecharge_Val
          CALPRM_CFLR_Rport_KeCFLR_b_NegativeFlt_CAN_En: accessed-parameter=CFLR_Rport.KeCFLR_b_NegativeFlt_CAN_En
          CALPRM_CFLR_Rport_KeCFLR_b_NegativeStuckCloseFlt_En: accessed-parameter=CFLR_Rport.KeCFLR_b_NegativeStuckCloseFlt_En
          CALPRM_CFLR_Rport_KeCFLR_b_NegativeStuckOpenFlt_En: accessed-parameter=CFLR_Rport.KeCFLR_b_NegativeStuckOpenFlt_En
          CALPRM_CFLR_Rport_KeCFLR_b_PassiveMcuDischarge_En: accessed-parameter=CFLR_Rport.KeCFLR_b_PassiveMcuDischarge_En
          CALPRM_CFLR_Rport_KeCFLR_b_PositiveFlt_CAN_En: accessed-parameter=CFLR_Rport.KeCFLR_b_PositiveFlt_CAN_En
          CALPRM_CFLR_Rport_KeCFLR_b_PositiveStuckCloseFlt_En: accessed-parameter=CFLR_Rport.KeCFLR_b_PositiveStuckCloseFlt_En
          CALPRM_CFLR_Rport_KeCFLR_b_PositiveStuckOpenFlt_En: accessed-parameter=CFLR_Rport.KeCFLR_b_PositiveStuckOpenFlt_En
          CALPRM_CFLR_Rport_KeCFLR_b_PreChargeFailFlt_En: accessed-parameter=CFLR_Rport.KeCFLR_b_PreChargeFailFlt_En
          CALPRM_CFLR_Rport_KeCFLR_b_PreChargeOvCur_flt_En: accessed-parameter=CFLR_Rport.KeCFLR_b_PreChargeOvCur_flt_En
          CALPRM_CFLR_Rport_KeCFLR_b_PreResistorStuckOpenFlt_En: accessed-parameter=CFLR_Rport.KeCFLR_b_PreResistorStuckOpenFlt_En
          CALPRM_CFLR_Rport_KeCFLR_b_PrechargeFlt_CAN_En: accessed-parameter=CFLR_Rport.KeCFLR_b_PrechargeFlt_CAN_En
          CALPRM_CFLR_Rport_KeCFLR_b_PrechargeStuckCloseFlt_En: accessed-parameter=CFLR_Rport.KeCFLR_b_PrechargeStuckCloseFlt_En
          CALPRM_CFLR_Rport_KeCFLR_b_PrechargeStuckOpenFlt_En: accessed-parameter=CFLR_Rport.KeCFLR_b_PrechargeStuckOpenFlt_En
          CALPRM_CFLR_Rport_KeCFLR_b_RelayOverLoad_En: accessed-parameter=CFLR_Rport.KeCFLR_b_RelayOverLoad_En
          CALPRM_CFLR_Rport_KeCFLR_b_StartReadPackToLinkV_drv_En: accessed-parameter=CFLR_Rport.KeCFLR_b_StartReadPackToLinkV_drv_En
          CALPRM_CFLR_Rport_KeCFLR_b_StartReadPackToLinkV_drv_Val: accessed-parameter=CFLR_Rport.KeCFLR_b_StartReadPackToLinkV_drv_Val
          CALPRM_CFLR_Rport_KeCFLR_b_UnexpectedContOpen_flt_En: accessed-parameter=CFLR_Rport.KeCFLR_b_UnexpectedContOpen_flt_En
          CALPRM_CFLR_Rport_KeCFLR_e_PrechgSt_En: accessed-parameter=CFLR_Rport.KeCFLR_e_PrechgSt_En
          CALPRM_CFLR_Rport_KeCFLR_e_PrechgSt_Val: accessed-parameter=CFLR_Rport.KeCFLR_e_PrechgSt_Val
          CALPRM_CFLR_Rport_KeCFLR_k_ActiveMcuDischarge_Val: accessed-parameter=CFLR_Rport.KeCFLR_k_ActiveMcuDischarge_Val
          CALPRM_CFLR_Rport_KeCFLR_k_ConDrvHeatCircuit_flt_Val: accessed-parameter=CFLR_Rport.KeCFLR_k_ConDrvHeatCircuit_flt_Val
          CALPRM_CFLR_Rport_KeCFLR_k_ConDrvNegCircuit_flt_Val: accessed-parameter=CFLR_Rport.KeCFLR_k_ConDrvNegCircuit_flt_Val
          CALPRM_CFLR_Rport_KeCFLR_k_ConDrvPosCircuit_flt_Val: accessed-parameter=CFLR_Rport.KeCFLR_k_ConDrvPosCircuit_flt_Val
          CALPRM_CFLR_Rport_KeCFLR_k_ConDrvPreCircuit_flt_Val: accessed-parameter=CFLR_Rport.KeCFLR_k_ConDrvPreCircuit_flt_Val
          CALPRM_CFLR_Rport_KeCFLR_k_DiagCounterCmd_En: accessed-parameter=CFLR_Rport.KeCFLR_k_DiagCounterCmd_En
          CALPRM_CFLR_Rport_KeCFLR_k_DiagCounterCmd_Val: accessed-parameter=CFLR_Rport.KeCFLR_k_DiagCounterCmd_Val
          CALPRM_CFLR_Rport_KeCFLR_k_HVClosingReq_Val: accessed-parameter=CFLR_Rport.KeCFLR_k_HVClosingReq_Val
          CALPRM_CFLR_Rport_KeCFLR_k_HeatCntctr1_OverrideAck_Val: accessed-parameter=CFLR_Rport.KeCFLR_k_HeatCntctr1_OverrideAck_Val
          CALPRM_CFLR_Rport_KeCFLR_k_HeatStuckClose_flt_Val: accessed-parameter=CFLR_Rport.KeCFLR_k_HeatStuckClose_flt_Val
          CALPRM_CFLR_Rport_KeCFLR_k_HeatStuckOpen_flt_Val: accessed-parameter=CFLR_Rport.KeCFLR_k_HeatStuckOpen_flt_Val
          CALPRM_CFLR_Rport_KeCFLR_k_MSDOpenFlt_Val: accessed-parameter=CFLR_Rport.KeCFLR_k_MSDOpenFlt_Val
          CALPRM_CFLR_Rport_KeCFLR_k_MainFuse1Open_Val: accessed-parameter=CFLR_Rport.KeCFLR_k_MainFuse1Open_Val
          CALPRM_CFLR_Rport_KeCFLR_k_MainFuse2Open_Val: accessed-parameter=CFLR_Rport.KeCFLR_k_MainFuse2Open_Val
          CALPRM_CFLR_Rport_KeCFLR_k_NegativeFlt_CAN_Val: accessed-parameter=CFLR_Rport.KeCFLR_k_NegativeFlt_CAN_Val
          CALPRM_CFLR_Rport_KeCFLR_k_NegativeStuckCloseFlt_Val: accessed-parameter=CFLR_Rport.KeCFLR_k_NegativeStuckCloseFlt_Val
          CALPRM_CFLR_Rport_KeCFLR_k_NegativeStuckOpenFlt_Val: accessed-parameter=CFLR_Rport.KeCFLR_k_NegativeStuckOpenFlt_Val
          CALPRM_CFLR_Rport_KeCFLR_k_PassiveMcuDischarge_Val: accessed-parameter=CFLR_Rport.KeCFLR_k_PassiveMcuDischarge_Val
          CALPRM_CFLR_Rport_KeCFLR_k_PositiveFlt_CAN_Val: accessed-parameter=CFLR_Rport.KeCFLR_k_PositiveFlt_CAN_Val
          CALPRM_CFLR_Rport_KeCFLR_k_PositiveStuckCloseFlt_Val: accessed-parameter=CFLR_Rport.KeCFLR_k_PositiveStuckCloseFlt_Val
          CALPRM_CFLR_Rport_KeCFLR_k_PositiveStuckOpenFlt_Val: accessed-parameter=CFLR_Rport.KeCFLR_k_PositiveStuckOpenFlt_Val
          CALPRM_CFLR_Rport_KeCFLR_k_PreChargeFailFlt_Val: accessed-parameter=CFLR_Rport.KeCFLR_k_PreChargeFailFlt_Val
          CALPRM_CFLR_Rport_KeCFLR_k_PreChargeOvCur_flt_Val: accessed-parameter=CFLR_Rport.KeCFLR_k_PreChargeOvCur_flt_Val
          CALPRM_CFLR_Rport_KeCFLR_k_PreResistorStuckOpenFlt_Val: accessed-parameter=CFLR_Rport.KeCFLR_k_PreResistorStuckOpenFlt_Val
          CALPRM_CFLR_Rport_KeCFLR_k_PrechargeFlt_CAN_Val: accessed-parameter=CFLR_Rport.KeCFLR_k_PrechargeFlt_CAN_Val
          CALPRM_CFLR_Rport_KeCFLR_k_PrechargeStuckCloseFlt_Val: accessed-parameter=CFLR_Rport.KeCFLR_k_PrechargeStuckCloseFlt_Val
          CALPRM_CFLR_Rport_KeCFLR_k_PrechargeStuckOpenFlt_Val: accessed-parameter=CFLR_Rport.KeCFLR_k_PrechargeStuckOpenFlt_Val
          CALPRM_CFLR_Rport_KeCFLR_k_RelayOverLoad_Val: accessed-parameter=CFLR_Rport.KeCFLR_k_RelayOverLoad_Val
          CALPRM_CFLR_Rport_KeCFLR_k_UnexpectedContOpen_flt_Val: accessed-parameter=CFLR_Rport.KeCFLR_k_UnexpectedContOpen_flt_Val
          CALPRM_CFLR_Rport_KeCFLR_n_NumofFails: accessed-parameter=CFLR_Rport.KeCFLR_n_NumofFails
          CALPRM_CFLR_Rport_KeCFLR_r_PrechargeTrGain: accessed-parameter=CFLR_Rport.KeCFLR_r_PrechargeTrGain
          CALPRM_CFLR_Rport_KeCFLR_t_ActuatorWaitTime: accessed-parameter=CFLR_Rport.KeCFLR_t_ActuatorWaitTime
          CALPRM_CFLR_Rport_KeCFLR_t_ContactorBasicDiffDebounceOffTime: accessed-parameter=CFLR_Rport.KeCFLR_t_ContactorBasicDiffDebounceOffTime
          CALPRM_CFLR_Rport_KeCFLR_t_ContactorBasicDiffDebounceOnTime: accessed-parameter=CFLR_Rport.KeCFLR_t_ContactorBasicDiffDebounceOnTime
          CALPRM_CFLR_Rport_KeCFLR_t_ContactorDRV_Ts: accessed-parameter=CFLR_Rport.KeCFLR_t_ContactorDRV_Ts
          CALPRM_CFLR_Rport_KeCFLR_t_ContactorDiagFncCallRate: accessed-parameter=CFLR_Rport.KeCFLR_t_ContactorDiagFncCallRate
          CALPRM_CFLR_Rport_KeCFLR_t_ContctrErrorDbnc: accessed-parameter=CFLR_Rport.KeCFLR_t_ContctrErrorDbnc
          CALPRM_CFLR_Rport_KeCFLR_t_DebounceTimeforCurrValidity: accessed-parameter=CFLR_Rport.KeCFLR_t_DebounceTimeforCurrValidity
          CALPRM_CFLR_Rport_KeCFLR_t_InitW8Time: accessed-parameter=CFLR_Rport.KeCFLR_t_InitW8Time
          CALPRM_CFLR_Rport_KeCFLR_t_MaxTimeB4ContactForcedOpen: accessed-parameter=CFLR_Rport.KeCFLR_t_MaxTimeB4ContactForcedOpen
          CALPRM_CFLR_Rport_KeCFLR_t_MaxTimeCurrCheck: accessed-parameter=CFLR_Rport.KeCFLR_t_MaxTimeCurrCheck
          CALPRM_CFLR_Rport_KeCFLR_t_MaxTimeInitState: accessed-parameter=CFLR_Rport.KeCFLR_t_MaxTimeInitState
          CALPRM_CFLR_Rport_KeCFLR_t_MaxTimeVoltCheck: accessed-parameter=CFLR_Rport.KeCFLR_t_MaxTimeVoltCheck
          CALPRM_CFLR_Rport_KeCFLR_t_MaxWaitTimeNegConOpn: accessed-parameter=CFLR_Rport.KeCFLR_t_MaxWaitTimeNegConOpn
          CALPRM_CFLR_Rport_KeCFLR_t_MaxWaitTimePosConClos: accessed-parameter=CFLR_Rport.KeCFLR_t_MaxWaitTimePosConClos
          CALPRM_CFLR_Rport_KeCFLR_t_MaxWaitTimePosConOpn: accessed-parameter=CFLR_Rport.KeCFLR_t_MaxWaitTimePosConOpn
          CALPRM_CFLR_Rport_KeCFLR_t_MinTimeAlwdB4CurrCheck: accessed-parameter=CFLR_Rport.KeCFLR_t_MinTimeAlwdB4CurrCheck
          CALPRM_CFLR_Rport_KeCFLR_t_MinTimeInitState: accessed-parameter=CFLR_Rport.KeCFLR_t_MinTimeInitState
          CALPRM_CFLR_Rport_KeCFLR_t_MinTimeinGPIO_State: accessed-parameter=CFLR_Rport.KeCFLR_t_MinTimeinGPIO_State
          CALPRM_CFLR_Rport_KeCFLR_t_PreChFaulRst: accessed-parameter=CFLR_Rport.KeCFLR_t_PreChFaulRst
          CALPRM_CFLR_Rport_KeCFLR_t_PreChFaulSet: accessed-parameter=CFLR_Rport.KeCFLR_t_PreChFaulSet
          CALPRM_CFLR_Rport_KeCFLR_t_PreChOverCurrDebounceOnTime: accessed-parameter=CFLR_Rport.KeCFLR_t_PreChOverCurrDebounceOnTime
          CALPRM_CFLR_Rport_KeCFLR_t_SM_Timer: accessed-parameter=CFLR_Rport.KeCFLR_t_SM_Timer
          CALPRM_CFLR_Rport_KeCFLR_t_Test1MaxWait: accessed-parameter=CFLR_Rport.KeCFLR_t_Test1MaxWait
          CALPRM_CFLR_Rport_KeCFLR_t_Test1MinWait: accessed-parameter=CFLR_Rport.KeCFLR_t_Test1MinWait
          CALPRM_CFLR_Rport_KeCFLR_t_Test21MaxWait: accessed-parameter=CFLR_Rport.KeCFLR_t_Test21MaxWait
          CALPRM_CFLR_Rport_KeCFLR_t_Test21MinWait: accessed-parameter=CFLR_Rport.KeCFLR_t_Test21MinWait
          CALPRM_CFLR_Rport_KeCFLR_t_Test22MaxWait: accessed-parameter=CFLR_Rport.KeCFLR_t_Test22MaxWait
          CALPRM_CFLR_Rport_KeCFLR_t_Test22MinWait: accessed-parameter=CFLR_Rport.KeCFLR_t_Test22MinWait
          CALPRM_CFLR_Rport_KeCFLR_t_Test2MaxWait: accessed-parameter=CFLR_Rport.KeCFLR_t_Test2MaxWait
          CALPRM_CFLR_Rport_KeCFLR_t_Test2MinWait: accessed-parameter=CFLR_Rport.KeCFLR_t_Test2MinWait
          CALPRM_CFLR_Rport_KeCFLR_t_Test31MaxWait: accessed-parameter=CFLR_Rport.KeCFLR_t_Test31MaxWait
          CALPRM_CFLR_Rport_KeCFLR_t_Test31MinWait: accessed-parameter=CFLR_Rport.KeCFLR_t_Test31MinWait
          CALPRM_CFLR_Rport_KeCFLR_t_Test32MaxWait: accessed-parameter=CFLR_Rport.KeCFLR_t_Test32MaxWait
          CALPRM_CFLR_Rport_KeCFLR_t_Test32MinWait: accessed-parameter=CFLR_Rport.KeCFLR_t_Test32MinWait
          CALPRM_CFLR_Rport_KeCFLR_t_Test33MaxWait: accessed-parameter=CFLR_Rport.KeCFLR_t_Test33MaxWait
          CALPRM_CFLR_Rport_KeCFLR_t_Test33MinWait: accessed-parameter=CFLR_Rport.KeCFLR_t_Test33MinWait
          CALPRM_CFLR_Rport_KeCFLR_t_Test41MaxWait: accessed-parameter=CFLR_Rport.KeCFLR_t_Test41MaxWait
          CALPRM_CFLR_Rport_KeCFLR_t_Test41MinWait: accessed-parameter=CFLR_Rport.KeCFLR_t_Test41MinWait
          CALPRM_CFLR_Rport_KeCFLR_t_Test42MaxWait: accessed-parameter=CFLR_Rport.KeCFLR_t_Test42MaxWait
      7 x swc service dependency:
        SwcNv_NeCFLR_t_InitW8Time: assigned-datas=role-based-data-assignment={role=ramBlock, used-pim=NeCFLR_t_InitW8Time}
          service-needs:
            nv block needs SwcNv_NeCFLR_t_InitW8Time: restore-at-start=true, store-at-shutdown=true
        SwcNv_NaCFLR_t_PreChTimer: assigned-datas=role-based-data-assignment={role=ramBlock, used-pim=NaCFLR_t_PreChTimer}
          service-needs:
            nv block needs SwcNv_NaCFLR_t_PreChTimer: restore-at-start=true, store-at-shutdown=true
        SwcNv_NeCFLR_t_LifeTime: assigned-datas=role-based-data-assignment={role=ramBlock, used-pim=NeCFLR_t_LifeTime}
          service-needs:
            nv block needs SwcNv_NeCFLR_t_LifeTime: restore-at-start=true, store-at-shutdown=true
        SwcNv_NeCFLR_Cnt_FaultCounter: assigned-datas=role-based-data-assignment={role=ramBlock, used-pim=NeCFLR_Cnt_FaultCounter}
          service-needs:
            nv block needs SwcNv_NeCFLR_Cnt_FaultCounter: restore-at-start=true, store-at-shutdown=true
        SwcNv_NeCFLR_k_PreStart: assigned-datas=role-based-data-assignment={role=ramBlock, used-pim=NeCFLR_k_PreStart}
          service-needs:
            nv block needs SwcNv_NeCFLR_k_PreStart: restore-at-start=true, store-at-shutdown=true
        SwcNv_NeCFLR_k_PreEnd: assigned-datas=role-based-data-assignment={role=ramBlock, used-pim=NeCFLR_k_PreEnd}
          service-needs:
            nv block needs SwcNv_NeCFLR_k_PreEnd: restore-at-start=true, store-at-shutdown=true
        SwcNv_NeCFLR_b_PreChProtect: assigned-datas=role-based-data-assignment={role=ramBlock, used-pim=NeCFLR_b_PreChProtect}
          service-needs:
            nv block needs SwcNv_NeCFLR_b_PreChProtect: restore-at-start=true, store-at-shutdown=true
package /CalibrationComponents
  parameter sw component type CFLR: data-type-mapping=CFLR_CodeDataTypeMappingsSet
    provide port CFLR_Pport: provided-interface=CFLR_if
      provided-com-specs:
        init-value=CFLR_Pport_KaCFLR_t_PreChTimer:5 x -0.10000000149011612, parameter=KaCFLR_t_PreChTimer
        init-value=0.25, parameter=KeCFLR_I_CntctrCurrHoldHeat
        init-value=0.44999998807907104, parameter=KeCFLR_I_CntctrCurrHoldNeg
        init-value=0.44999998807907104, parameter=KeCFLR_I_CntctrCurrHoldPos
        init-value=0.25, parameter=KeCFLR_I_CntctrCurrHoldPre
        init-value=0.25, parameter=KeCFLR_I_MaxCurrOpenCntctr
        init-value=1, parameter=KeCFLR_I_MaxR3Current
        init-value=-0.25, parameter=KeCFLR_I_MinCurrOpenCntctr
        init-value=-1, parameter=KeCFLR_I_MinR3Current
        init-value=6, parameter=KeCFLR_I_OverCurrentThresh
        init-value=2, parameter=KeCFLR_I_PowDownCurrentThresh
        init-value=-1, parameter=KeCFLR_I_ZeroCurrentThreshholdLw
        init-value=1, parameter=KeCFLR_I_ZeroCurrentThreshholdUp
        init-value=0.92, parameter=KeCFLR_K_KL30VoltageFactorLower
        init-value=1.08, parameter=KeCFLR_K_KL30VoltageFactorUpper
        init-value=0, parameter=KeCFLR_Pct_ContctrPWM_Fsp_drv_Val
        init-value=0, parameter=KeCFLR_Pct_ContctrPWM_Neg_drv_Val
        init-value=0, parameter=KeCFLR_Pct_ContctrPWM_Pre_drv_Val
        init-value=0, parameter=KeCFLR_Pct_SetContctrPWM_PIDPos_Val
        init-value=19.200000762939453, parameter=KeCFLR_R_PosResistanceLowLim
        init-value=28.799999237060547, parameter=KeCFLR_R_PosResistanceUpLim
        init-value=38.400001525878906, parameter=KeCFLR_R_PreResistanceLowLim
        init-value=57.599998474121094, parameter=KeCFLR_R_PreResistanceUpLim
        init-value=0.20000000298023224, parameter=KeCFLR_U_GroundVoltageHigh
        init-value=0.019999999552965164, parameter=KeCFLR_U_GroundVoltageLow
        init-value=0.949999988079071, parameter=KeCFLR_U_LinkLessThanPack
        init-value=18, parameter=KeCFLR_U_MaxOSM_Voltage
        init-value=1, parameter=KeCFLR_U_MaxVolt4HS_OSMPos
        init-value=0.550000011920929, parameter=KeCFLR_U_MaxVolt4HS_OSMPre
        init-value=1, parameter=KeCFLR_U_MaxVolt4LS_OSMPos
        init-value=0.550000011920929, parameter=KeCFLR_U_MaxVolt4LS_OSMPre
        init-value=60, parameter=KeCFLR_U_McuDischgThreshhold
        init-value=2, parameter=KeCFLR_U_MinCoilVoltageAllowed
        init-value=6, parameter=KeCFLR_U_MinOSM_Voltage
        init-value=-1, parameter=KeCFLR_U_MinVolt4HS_OSMPos
        init-value=0.3499999940395355, parameter=KeCFLR_U_MinVolt4HS_OSMPre
        init-value=-1, parameter=KeCFLR_U_MinVolt4LS_OSMPos
        init-value=0.3499999940395355, parameter=KeCFLR_U_MinVolt4LS_OSMPre
        init-value=10, parameter=KeCFLR_U_NegConClosedThreshhold
        init-value=15, parameter=KeCFLR_U_PowerdiffThreshhold
        init-value=50, parameter=KeCFLR_U_withPowerThreshhold
        init-value=0.9800000190734863, parameter=KeCFLR_r_PrechargeTrGain
        init-value=0.05000000074505806, parameter=KeCFLR_t_ActuatorWaitTime
        init-value=0.009999999776482582, parameter=KeCFLR_t_CoilVoltageDebouce
        init-value=0.05000000074505806, parameter=KeCFLR_t_ContactorBasicDiffDebounceOffTime
        init-value=0.05000000074505806, parameter=KeCFLR_t_ContactorBasicDiffDebounceOnTime
        init-value=0.009999999776482582, parameter=KeCFLR_t_ContactorDRV_Ts
        init-value=0.009999999776482582, parameter=KeCFLR_t_ContactorDiagFncCallRate
        init-value=0.05000000074505806, parameter=KeCFLR_t_ContactorDrivePIDCatchup
        init-value=0.15000000596046448, parameter=KeCFLR_t_ContactorStateMachineTimeout{1..5}
        init-value=5, parameter=KeCFLR_t_ContctrErrorDbnc
        init-value=0.009999999776482582, parameter=KeCFLR_t_DebounceTimeforCurrValidity
        init-value=0.07500000298023224, parameter=KeCFLR_t_InitW8Time
        init-value=10, parameter=KeCFLR_t_MaxTimeB4ContactForcedOpen
        init-value=0.05000000074505806, parameter=KeCFLR_t_MaxTimeCurrCheck
        init-value=0.05000000074505806, parameter=KeCFLR_t_MaxTimeInitState
        init-value=0.05000000074505806, parameter=KeCFLR_t_MaxTimeVoltCheck
        init-value=0.05000000074505806, parameter=KeCFLR_t_MaxTimeVoltDiffCheck
        init-value=0.07500000298023224, parameter=KeCFLR_t_MaxWaitTimeNegConOpn
        init-value=0.15000000596046448, parameter=KeCFLR_t_MaxWaitTimePosConClos
        init-value=0.07500000298023224, parameter=KeCFLR_t_MaxWaitTimePosConOpn
        init-value=0.009999999776482582, parameter=KeCFLR_t_MinTimeAlwdB4CurrCheck
        init-value=0.009999999776482582, parameter=KeCFLR_t_MinTimeInitState
        init-value=0.019999999552965164, parameter=KeCFLR_t_MinTimeinGPIO_State
        init-value=30, parameter=KeCFLR_t_PreChFaulRst
        init-value=30, parameter=KeCFLR_t_PreChFaulSet
        init-value=0.20000000298023224, parameter=KeCFLR_t_PreChOverCurrDebounceOnTime
        init-value=0.009999999776482582, parameter=KeCFLR_t_SM_Timer
        init-value=0.25, parameter=KeCFLR_t_Test1MaxWait
        init-value=0.15000000596046448, parameter=KeCFLR_t_Test1MinWait
        init-value=2, parameter=KeCFLR_t_Test21MaxWait
        init-value=0.20000000298023224, parameter=KeCFLR_t_Test21MinWait
        init-value=78, parameter=KeCFLR_t_Test22MaxWait
        init-value=0.05000000074505806, parameter=KeCFLR_t_Test22MinWait
        init-value=0.20000000298023224, parameter=KeCFLR_t_Test2MaxWait
        init-value=0.10000000149011612, parameter=KeCFLR_t_Test2MinWait
        init-value=0.800000011920929, parameter=KeCFLR_t_Test31MaxWait
        init-value=0.30000001192092896, parameter=KeCFLR_t_Test31MinWait
        init-value=0.20000000298023224, parameter=KeCFLR_t_Test32MaxWait
        init-value=0.10000000149011612, parameter=KeCFLR_t_Test32MinWait
        init-value=0.11999999731779099, parameter=KeCFLR_t_Test33MaxWait
        init-value=0.07999999821186066, parameter=KeCFLR_t_Test33MinWait
        init-value=1, parameter=KeCFLR_t_Test41MaxWait
        init-value=0.5, parameter=KeCFLR_t_Test41MinWait
        init-value=1, parameter=KeCFLR_t_Test42MaxWait
        init-value=300, parameter=KeCFLR_Cnt_ClrPrechgProtectTime1
        init-value=2000, parameter=KeCFLR_Cnt_ClrPrechgProtectTime2
        init-value=500, parameter=KeCFLR_Cnt_PowDownTimeThresh
        init-value=CeCFLR_e_PrechgDefault, parameter=KeCFLR_e_PrechgSt_Val
        init-value=0, parameter=KeCFLR_Pct_ContctrPWM_Pre_drv_En
        init-value=0, parameter=KeCFLR_Pct_SetContctrPWM_PIDPos_En
        init-value=0, parameter=KeCFLR_b_ActiveMcuDischarge_En
        init-value=0, parameter=KeCFLR_b_CloseHeat_En
        init-value=0, parameter=KeCFLR_b_CloseHeat_Val
        init-value=0, parameter=KeCFLR_b_CloseNeg_En
        init-value=0, parameter=KeCFLR_b_CloseNeg_Val
        init-value=0, parameter=KeCFLR_b_ClosePos_En
        init-value=0, parameter=KeCFLR_b_ClosePos_Val
        init-value=0, parameter=KeCFLR_b_ClosePre_En
        init-value=0, parameter=KeCFLR_b_ClosePre_Val
        init-value=0, parameter=KeCFLR_b_ConDrvHeatCircuit_flt_En
        init-value=0, parameter=KeCFLR_b_ConDrvNegCircuit_flt_En
        init-value=0, parameter=KeCFLR_b_ConDrvPosCircuit_flt_En
        init-value=0, parameter=KeCFLR_b_ConDrvPreCircuit_flt_En
        init-value=0, parameter=KeCFLR_b_ContactorsClosed_En
        init-value=0, parameter=KeCFLR_b_ContactorsClosed_Val
        init-value=0, parameter=KeCFLR_b_ContctrPWM_Fsp_drv_En
        init-value=0, parameter=KeCFLR_b_ContctrPWM_Neg_drv_En
        init-value=0, parameter=KeCFLR_b_EnableContactorsDiag_En
        init-value=0, parameter=KeCFLR_b_EnableContactorsDiag_Val
        init-value=0, parameter=KeCFLR_b_EnblGPIOHeat_drv_En
        init-value=0, parameter=KeCFLR_b_EnblGPIOHeat_drv_Val
        init-value=0, parameter=KeCFLR_b_EnblGPIONeg_drv_En
        init-value=0, parameter=KeCFLR_b_EnblGPIONeg_drv_Val
        init-value=0, parameter=KeCFLR_b_EnblGPIOPos_drv_En
        init-value=0, parameter=KeCFLR_b_EnblGPIOPos_drv_Val
        init-value=0, parameter=KeCFLR_b_EnblGPIOPre_drv_En
        init-value=0, parameter=KeCFLR_b_EnblGPIOPre_drv_Val
        init-value=0, parameter=KeCFLR_b_Force2InitNeg
        init-value=0, parameter=KeCFLR_b_ForceOpenContactors
        init-value=0, parameter=KeCFLR_b_HVClosingReq_En
        init-value=0, parameter=KeCFLR_b_HVFaultReady_En
        init-value=0, parameter=KeCFLR_b_HVFaultReady_Val
        init-value=0, parameter=KeCFLR_b_HeatClosed_En
        init-value=0, parameter=KeCFLR_b_HeatClosed_Val
        init-value=0, parameter=KeCFLR_b_HeatCntctr1_OverrideAck_En
        init-value=0, parameter=KeCFLR_b_HeatConClosed_En
        init-value=0, parameter=KeCFLR_b_HeatConClosed_Val
        init-value=0, parameter=KeCFLR_b_HeatStuckClose_flt_En
        init-value=0, parameter=KeCFLR_b_HeatStuckOpen_flt_En
        init-value=0, parameter=KeCFLR_b_MSDOpenFlt_En
        init-value=0, parameter=KeCFLR_b_MainFuse1Open_En
        init-value=0, parameter=KeCFLR_b_MainFuse2Open_En
        init-value=0, parameter=KeCFLR_b_MainNegative_En
        init-value=0, parameter=KeCFLR_b_MainNegative_Val
        init-value=0, parameter=KeCFLR_b_MainPositive_En
        init-value=0, parameter=KeCFLR_b_MainPositive_Val
        init-value=0, parameter=KeCFLR_b_MainPrecharge_En
        init-value=0, parameter=KeCFLR_b_MainPrecharge_Val
        init-value=0, parameter=KeCFLR_b_NegativeFlt_CAN_En
        init-value=0, parameter=KeCFLR_b_NegativeStuckCloseFlt_En
        init-value=0, parameter=KeCFLR_b_NegativeStuckOpenFlt_En
        init-value=0, parameter=KeCFLR_b_PassiveMcuDischarge_En
        init-value=0, parameter=KeCFLR_b_PositiveFlt_CAN_En
        init-value=0, parameter=KeCFLR_b_PositiveStuckCloseFlt_En
        init-value=0, parameter=KeCFLR_b_PositiveStuckOpenFlt_En
        init-value=0, parameter=KeCFLR_b_PreChargeFailFlt_En
        init-value=0, parameter=KeCFLR_b_PreChargeOvCur_flt_En
        init-value=0, parameter=KeCFLR_b_PreResistorStuckOpenFlt_En
        init-value=0, parameter=KeCFLR_b_PrechargeFlt_CAN_En
        init-value=0, parameter=KeCFLR_b_PrechargeStuckCloseFlt_En
        init-value=0, parameter=KeCFLR_b_PrechargeStuckOpenFlt_En
        init-value=0, parameter=KeCFLR_b_RelayOverLoad_En
        init-value=0, parameter=KeCFLR_b_StartReadPackToLinkV_drv_En
        init-value=0, parameter=KeCFLR_b_StartReadPackToLinkV_drv_Val
        init-value=0, parameter=KeCFLR_b_UnexpectedContOpen_flt_En
        init-value=0, parameter=KeCFLR_e_PrechgSt_En
        init-value=0, parameter=KeCFLR_k_DiagCounterCmd_En
        init-value=14, parameter=KeCFLR_Cnt_PreChgProtect
        init-value=0, parameter=KeCFLR_k_ActiveMcuDischarge_Val
        init-value=0, parameter=KeCFLR_k_ConDrvHeatCircuit_flt_Val
        init-value=0, parameter=KeCFLR_k_ConDrvNegCircuit_flt_Val
        init-value=0, parameter=KeCFLR_k_ConDrvPosCircuit_flt_Val
        init-value=0, parameter=KeCFLR_k_ConDrvPreCircuit_flt_Val
        init-value=0, parameter=KeCFLR_k_DiagCounterCmd_Val
        init-value=0, parameter=KeCFLR_k_HVClosingReq_Val
        init-value=0, parameter=KeCFLR_k_HeatCntctr1_OverrideAck_Val
        init-value=0, parameter=KeCFLR_k_HeatStuckClose_flt_Val
        init-value=0, parameter=KeCFLR_k_HeatStuckOpen_flt_Val
        init-value=0, parameter=KeCFLR_k_MSDOpenFlt_Val
        init-value=0, parameter=KeCFLR_k_MainFuse1Open_Val
        init-value=0, parameter=KeCFLR_k_MainFuse2Open_Val
        init-value=0, parameter=KeCFLR_k_NegativeFlt_CAN_Val
        init-value=0, parameter=KeCFLR_k_NegativeStuckCloseFlt_Val
        init-value=0, parameter=KeCFLR_k_NegativeStuckOpenFlt_Val
        init-value=0, parameter=KeCFLR_k_PassiveMcuDischarge_Val
        init-value=0, parameter=KeCFLR_k_PositiveFlt_CAN_Val
        init-value=0, parameter=KeCFLR_k_PositiveStuckCloseFlt_Val
        init-value=0, parameter=KeCFLR_k_PositiveStuckOpenFlt_Val
        init-value=0, parameter=KeCFLR_k_PreChargeFailFlt_Val
        init-value=0, parameter=KeCFLR_k_PreChargeOvCur_flt_Val
        init-value=0, parameter=KeCFLR_k_PreResistorStuckOpenFlt_Val
        init-value=0, parameter=KeCFLR_k_PrechargeFlt_CAN_Val
        init-value=0, parameter=KeCFLR_k_PrechargeStuckCloseFlt_Val
        init-value=0, parameter=KeCFLR_k_PrechargeStuckOpenFlt_Val
        init-value=0, parameter=KeCFLR_k_RelayOverLoad_Val
        init-value=0, parameter=KeCFLR_k_UnexpectedContOpen_flt_Val
        init-value=5, parameter=KeCFLR_n_NumofFails
